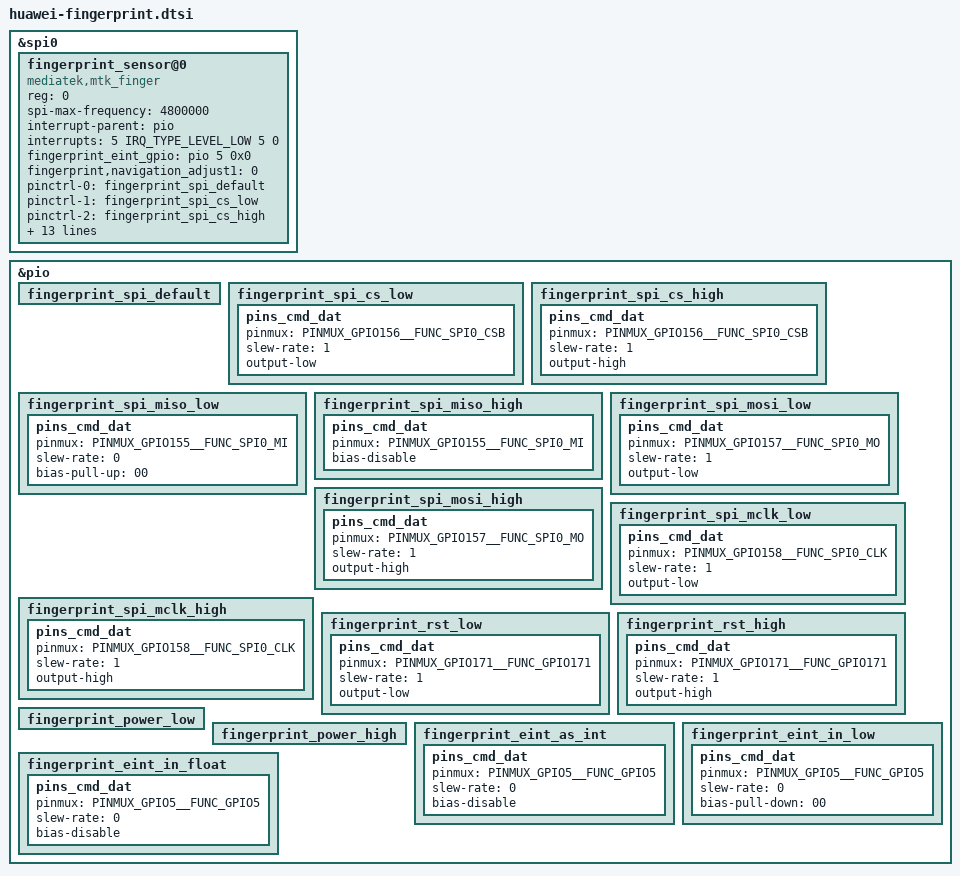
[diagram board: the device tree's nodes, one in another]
&spi0 {
	fingerprint_sensor@0 {
		compatible = "mediatek,mtk_finger";
		reg = <0>;
		spi-max-frequency = <4800000>;
		interrupt-parent = <&pio>;
		interrupts = <5 IRQ_TYPE_LEVEL_LOW 5 0>;

		fingerprint_eint_gpio = <&pio 5 0x0>;
		fingerprint,navigation_adjust1 = <0>;

		pinctrl-names = "fingerprint_spi_default", "fingerprint_spi_cs_low","fingerprint_spi_cs_high","fingerprint_spi_miso_low","fingerprint_spi_miso_high",
                    "fingerprint_spi_mosi_low","fingerprint_spi_mosi_high","fingerprint_spi_mclk_low","fingerprint_spi_mclk_high",
                    "fingerprint_rst_low","fingerprint_rst_high","fingerprint_power_low","fingerprint_power_high",
                    "fingerprint_eint_as_int","fingerprint_eint_in_low","fingerprint_eint_in_float";
		pinctrl-0 = <&fingerprint_spi_default>;
		pinctrl-1 = <&fingerprint_spi_cs_low>;
		pinctrl-2 = <&fingerprint_spi_cs_high>;
		pinctrl-3 = <&fingerprint_spi_miso_low>;
		pinctrl-4 = <&fingerprint_spi_miso_high>;
		pinctrl-5 = <&fingerprint_spi_mosi_low>;
		pinctrl-6 = <&fingerprint_spi_mosi_high>;
		pinctrl-7 = <&fingerprint_spi_mclk_low>;
		pinctrl-8 = <&fingerprint_spi_mclk_high>;
		pinctrl-9 = <&fingerprint_rst_low>;
		pinctrl-10 = <&fingerprint_rst_high>;
		pinctrl-11 = <&fingerprint_power_low>;
		pinctrl-12 = <&fingerprint_power_high>;
		pinctrl-13 = <&fingerprint_eint_as_int>;
		pinctrl-14 = <&fingerprint_eint_in_low>;
		pinctrl-15 = <&fingerprint_eint_in_float>;
		status = "okay";
	};
};

&pio {

	fingerprint_spi_default: fingerprint_spi_default {
	};

	fingerprint_spi_cs_low: fingerprint_spi_cs_low {
		pins_cmd_dat {
			pinmux = <PINMUX_GPIO156__FUNC_SPI0_CSB>;
			slew-rate = <1>;
			output-low;
		};
	};

	fingerprint_spi_cs_high: fingerprint_spi_cs_high {
		pins_cmd_dat {
			pinmux = <PINMUX_GPIO156__FUNC_SPI0_CSB>;
			slew-rate = <1>;
			output-high;
		};
	};
	fingerprint_spi_miso_low: fingerprint_spi_miso_low {
		pins_cmd_dat {
			pinmux = <PINMUX_GPIO155__FUNC_SPI0_MI>;
			slew-rate = <0>;
			bias-pull-up = <00>;
		};
	};
	fingerprint_spi_miso_high: fingerprint_spi_miso_high {
		pins_cmd_dat {
			pinmux = <PINMUX_GPIO155__FUNC_SPI0_MI>;
			bias-disable;
		};
	};
	fingerprint_spi_mosi_low: fingerprint_spi_mosi_low {
		pins_cmd_dat {
			pinmux = <PINMUX_GPIO157__FUNC_SPI0_MO>;
			slew-rate = <1>;
			output-low;
		};
	};
	fingerprint_spi_mosi_high: fingerprint_spi_mosi_high {
		pins_cmd_dat {
			pinmux = <PINMUX_GPIO157__FUNC_SPI0_MO>;
			slew-rate = <1>;
			output-high;
		};
	};
	fingerprint_spi_mclk_low: fingerprint_spi_mclk_low {
		pins_cmd_dat {
			pinmux = <PINMUX_GPIO158__FUNC_SPI0_CLK>;
			slew-rate = <1>;
			output-low;
		};
	};
	fingerprint_spi_mclk_high: fingerprint_spi_mclk_high {
		pins_cmd_dat {
			pinmux = <PINMUX_GPIO158__FUNC_SPI0_CLK>;
			slew-rate = <1>;
			output-high;
		};
	};
	fingerprint_rst_low: fingerprint_rst_low {
		pins_cmd_dat {
			pinmux = <PINMUX_GPIO171__FUNC_GPIO171>;
			slew-rate = <1>;
			output-low;
		};
	};
	fingerprint_rst_high: fingerprint_rst_high {
		pins_cmd_dat {
			pinmux = <PINMUX_GPIO171__FUNC_GPIO171>;
			slew-rate = <1>;
			output-high;
		};
	};
	fingerprint_power_low: fingerprint_power_low {

	};
	fingerprint_power_high: fingerprint_power_high {

	};
	fingerprint_eint_as_int: fingerprint_eint_as_int {
		pins_cmd_dat {
			pinmux = <PINMUX_GPIO5__FUNC_GPIO5>;
			slew-rate = <0>;
			bias-disable;
		};
	};
	fingerprint_eint_in_low: fingerprint_eint_in_low {
		pins_cmd_dat {
			pinmux = <PINMUX_GPIO5__FUNC_GPIO5>;
			slew-rate = <0>;
			bias-pull-down = <00>;
		};
	};
	fingerprint_eint_in_float: fingerprint_eint_in_float {
		pins_cmd_dat {
			pinmux = <PINMUX_GPIO5__FUNC_GPIO5>;
			slew-rate = <0>;
			bias-disable;
		};
	};
};

